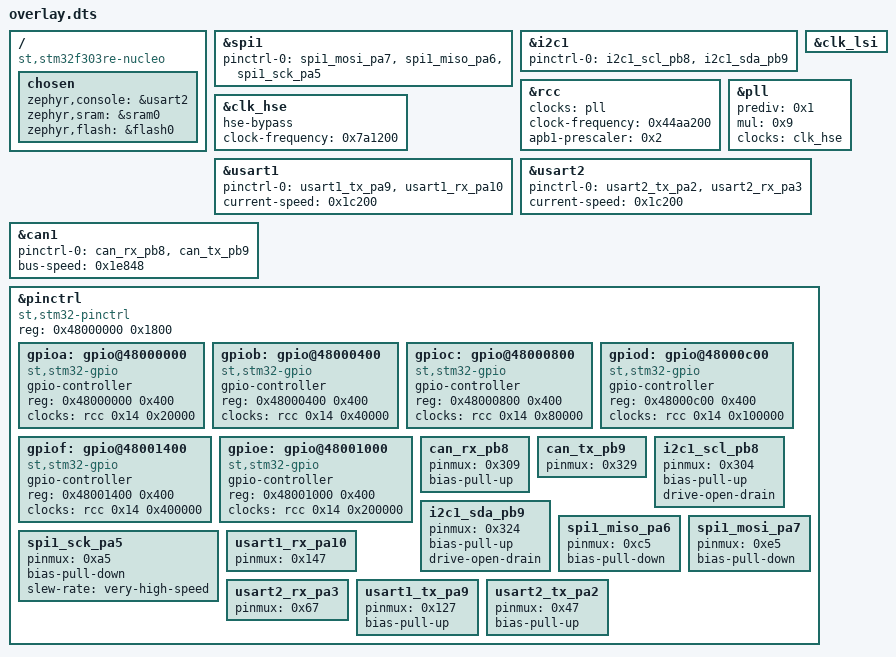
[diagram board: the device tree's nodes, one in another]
/ {
	compatible = "st,stm32f303re-nucleo";
	chosen {
		zephyr,console = &usart2;
		zephyr,sram = &sram0;
		zephyr,flash = &flash0;
	};
};
&spi1{
	status = "okay";
	pinctrl-0 = < &spi1_mosi_pa7 &spi1_miso_pa6 &spi1_sck_pa5 >;
	pinctrl-names = "default";
};
&i2c1{
	status = "okay";
	pinctrl-0 = < &i2c1_scl_pb8 &i2c1_sda_pb9 >;
	pinctrl-names = "default";
};
&clk_lsi{
	status = "okay";
};
&rcc{
	clocks = < &pll >;
	clock-frequency = < 0x44aa200 >;
	apb1-prescaler = < 0x2 >;
};
&clk_hse{
	status = "okay";
	hse-bypass;
	clock-frequency = < 0x7a1200 >;
};
&pll{
	status = "okay";
	prediv = < 0x1 >;
	mul = < 0x9 >;
	clocks = < &clk_hse >;
};
&usart1{
	status = "okay";
	pinctrl-0 = < &usart1_tx_pa9 &usart1_rx_pa10 >;
	pinctrl-names = "default";
	current-speed = < 0x1c200 >;
};
&usart2{
	status = "okay";
	pinctrl-0 = < &usart2_tx_pa2 &usart2_rx_pa3 >;
	pinctrl-names = "default";
	current-speed = < 0x1c200 >;
};
&can1{
	status = "okay";
	pinctrl-0 = < &can_rx_pb8 &can_tx_pb9 >;
	pinctrl-names = "default";
	bus-speed = < 0x1e848 >;
};
&pinctrl{
	compatible = "st,stm32-pinctrl";
	#address-cells = < 0x1 >;
	#size-cells = < 0x1 >;
	reg = < 0x48000000 0x1800 >;
	gpioa: gpio@48000000 {
		compatible = "st,stm32-gpio";
		gpio-controller;
		#gpio-cells = < 0x2 >;
		reg = < 0x48000000 0x400 >;
		clocks = < &rcc 0x14 0x20000 >;
	};
	gpiob: gpio@48000400 {
		compatible = "st,stm32-gpio";
		gpio-controller;
		#gpio-cells = < 0x2 >;
		reg = < 0x48000400 0x400 >;
		clocks = < &rcc 0x14 0x40000 >;
	};
	gpioc: gpio@48000800 {
		compatible = "st,stm32-gpio";
		gpio-controller;
		#gpio-cells = < 0x2 >;
		reg = < 0x48000800 0x400 >;
		clocks = < &rcc 0x14 0x80000 >;
	};
	gpiod: gpio@48000c00 {
		compatible = "st,stm32-gpio";
		gpio-controller;
		#gpio-cells = < 0x2 >;
		reg = < 0x48000c00 0x400 >;
		clocks = < &rcc 0x14 0x100000 >;
	};
	gpiof: gpio@48001400 {
		compatible = "st,stm32-gpio";
		gpio-controller;
		#gpio-cells = < 0x2 >;
		reg = < 0x48001400 0x400 >;
		clocks = < &rcc 0x14 0x400000 >;
	};
	gpioe: gpio@48001000 {
		compatible = "st,stm32-gpio";
		gpio-controller;
		#gpio-cells = < 0x2 >;
		reg = < 0x48001000 0x400 >;
		clocks = < &rcc 0x14 0x200000 >;
	};
	can_rx_pb8: can_rx_pb8 {
		pinmux = < 0x309 >;
		bias-pull-up;
	};
	can_tx_pb9: can_tx_pb9 {
		pinmux = < 0x329 >;
	};
	i2c1_scl_pb8: i2c1_scl_pb8 {
		pinmux = < 0x304 >;
		bias-pull-up;
		drive-open-drain;
	};
	i2c1_sda_pb9: i2c1_sda_pb9 {
		pinmux = < 0x324 >;
		bias-pull-up;
		drive-open-drain;
	};
	spi1_miso_pa6: spi1_miso_pa6 {
		pinmux = < 0xc5 >;
		bias-pull-down;
	};
	spi1_mosi_pa7: spi1_mosi_pa7 {
		pinmux = < 0xe5 >;
		bias-pull-down;
	};
	spi1_sck_pa5: spi1_sck_pa5 {
		pinmux = < 0xa5 >;
		bias-pull-down;
		slew-rate = "very-high-speed";
	};
	usart1_rx_pa10: usart1_rx_pa10 {
		pinmux = < 0x147 >;
	};
	usart2_rx_pa3: usart2_rx_pa3 {
		pinmux = < 0x67 >;
	};
	usart1_tx_pa9: usart1_tx_pa9 {
		pinmux = < 0x127 >;
		bias-pull-up;
	};
	usart2_tx_pa2: usart2_tx_pa2 {
		pinmux = < 0x47 >;
		bias-pull-up;
	};
};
